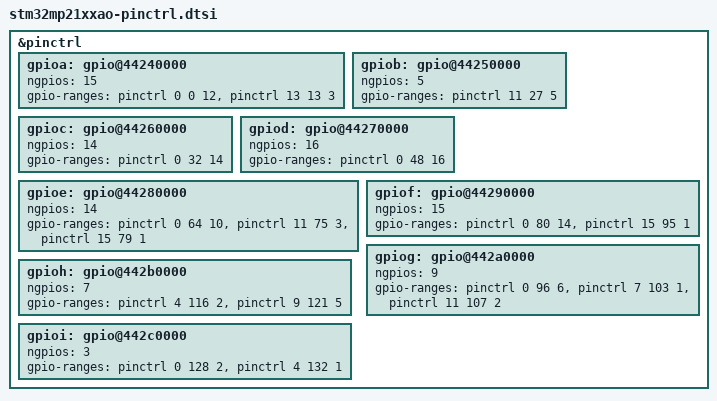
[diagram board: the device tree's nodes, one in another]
// SPDX-License-Identifier: (GPL-2.0-only OR BSD-3-Clause)
/*
 * Copyright (C) STMicroelectronics 2024 - All Rights Reserved
 * Author: Alexandre Torgue <alexandre.torgue@foss.st.com> for STMicroelectronics.
 */

&pinctrl {
	/omit-if-no-ref/
	gpioa: gpio@44240000 {
		status = "okay";
		ngpios = <15>;
		gpio-ranges = <&pinctrl 0 0 12>, <&pinctrl 13 13 3>;
	};

	/omit-if-no-ref/
	gpiob: gpio@44250000 {
		status = "okay";
		ngpios = <5>;
		gpio-ranges = <&pinctrl 11 27 5>;
	};

	/omit-if-no-ref/
	gpioc: gpio@44260000 {
		status = "okay";
		ngpios = <14>;
		gpio-ranges = <&pinctrl 0 32 14>;
	};

	/omit-if-no-ref/
	gpiod: gpio@44270000 {
		status = "okay";
		ngpios = <16>;
		gpio-ranges = <&pinctrl 0 48 16>;
	};

	/omit-if-no-ref/
	gpioe: gpio@44280000 {
		status = "okay";
		ngpios = <14>;
		gpio-ranges = <&pinctrl 0 64 10>, <&pinctrl 11 75 3>, <&pinctrl 15 79 1>;
	};

	/omit-if-no-ref/
	gpiof: gpio@44290000 {
		status = "okay";
		ngpios = <15>;
		gpio-ranges = <&pinctrl 0 80 14>, <&pinctrl 15 95 1>;
	};

	/omit-if-no-ref/
	gpiog: gpio@442a0000 {
		status = "okay";
		ngpios = <9>;
		gpio-ranges = <&pinctrl 0 96 6>, <&pinctrl 7 103 1>, <&pinctrl 11 107 2>;
	};

	/omit-if-no-ref/
	gpioh: gpio@442b0000 {
		status = "okay";
		ngpios = <7>;
		gpio-ranges = <&pinctrl 4 116 2>, <&pinctrl 9 121 5>;
	};

	/omit-if-no-ref/
	gpioi: gpio@442c0000 {
		status = "okay";
		ngpios = <3>;
		gpio-ranges = <&pinctrl 0 128 2>, <&pinctrl 4 132 1>;
	};
};
